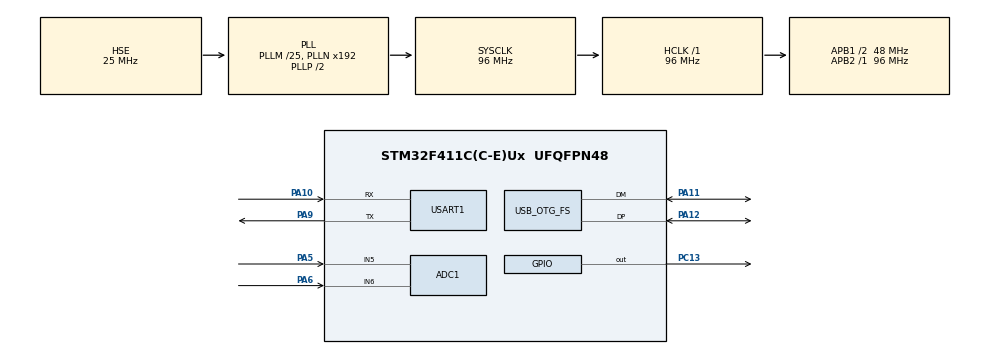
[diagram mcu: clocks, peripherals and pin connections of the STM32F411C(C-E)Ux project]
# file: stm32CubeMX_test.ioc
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ADC1.Channel-8\#ChannelRegularConversion=ADC_CHANNEL_5
ADC1.Channel-9\#ChannelRegularConversion=ADC_CHANNEL_6
ADC1.ClockPrescaler=ADC_CLOCK_SYNC_PCLK_DIV4
ADC1.InjNumberOfConversion=0
ADC1.NbrOfConversion=2
ADC1.NbrOfConversionFlag=1
ADC1.Rank-8\#ChannelRegularConversion=1
ADC1.Rank-9\#ChannelRegularConversion=2
ADC1.SamplingTime-8\#ChannelRegularConversion=ADC_SAMPLETIME_84CYCLES
ADC1.SamplingTime-9\#ChannelRegularConversion=ADC_SAMPLETIME_84CYCLES
ADC1.ScanConvMode=ENABLE
ADC1.master=1
Dma.ADC1.1.Direction=DMA_PERIPH_TO_MEMORY
Dma.ADC1.1.FIFOMode=DMA_FIFOMODE_DISABLE
Dma.ADC1.1.Instance=DMA2_Stream0
Dma.ADC1.1.MemDataAlignment=DMA_MDATAALIGN_HALFWORD
Dma.ADC1.1.MemInc=DMA_MINC_ENABLE
Dma.ADC1.1.Mode=DMA_NORMAL
Dma.ADC1.1.PeriphDataAlignment=DMA_PDATAALIGN_HALFWORD
Dma.ADC1.1.PeriphInc=DMA_PINC_DISABLE
Dma.ADC1.1.Priority=DMA_PRIORITY_LOW
Dma.Request0=USART1_TX
Dma.Request1=ADC1
Dma.USART1_TX.0.Direction=DMA_MEMORY_TO_PERIPH
Dma.USART1_TX.0.FIFOMode=DMA_FIFOMODE_DISABLE
Dma.USART1_TX.0.Instance=DMA2_Stream7
Dma.USART1_TX.0.MemDataAlignment=DMA_MDATAALIGN_BYTE
Dma.USART1_TX.0.MemInc=DMA_MINC_ENABLE
Dma.USART1_TX.0.Mode=DMA_NORMAL
Dma.USART1_TX.0.PeriphDataAlignment=DMA_PDATAALIGN_BYTE
Dma.USART1_TX.0.PeriphInc=DMA_PINC_DISABLE
Dma.USART1_TX.0.Priority=DMA_PRIORITY_MEDIUM
Mcu.Family=STM32F4
Mcu.Name=STM32F411C(C-E)Ux
Mcu.Package=UFQFPN48
NVIC.DMA2_Stream0_IRQn=true\:0\:0\:false\:false\:true\:false\:true\:true
NVIC.DMA2_Stream7_IRQn=true\:0\:0\:false\:false\:true\:false\:true\:true
NVIC.OTG_FS_IRQn=true\:0\:0\:false\:false\:true\:false\:true\:true
NVIC.PriorityGroup=NVIC_PRIORITYGROUP_4
NVIC.USART1_IRQn=true\:0\:0\:false\:false\:true\:true\:true\:true
PA10.Mode=Asynchronous
PA10.Signal=USART1_RX
PA11.Mode=Device_Only
PA11.Signal=USB_OTG_FS_DM
PA12.Mode=Device_Only
PA12.Signal=USB_OTG_FS_DP
PA5.Signal=ADCx_IN5
PA6.Signal=ADCx_IN6
PA9.Mode=Asynchronous
PA9.Signal=USART1_TX
PC13-ANTI_TAMP.Signal=GPIO_Output
PH0\ -\ OSC_IN.Mode=HSE-External-Oscillator
PH0\ -\ OSC_IN.Signal=RCC_OSC_IN
PH1\ -\ OSC_OUT.Mode=HSE-External-Oscillator
PH1\ -\ OSC_OUT.Signal=RCC_OSC_OUT
ProjectManager.HeapSize=0x1000
ProjectManager.StackSize=0x800
ProjectManager.TargetToolchain=STM32CubeIDE
RCC.48MHZClocksFreq_Value=48000000
RCC.AHBFreq_Value=96000000
RCC.APB1CLKDivider=RCC_HCLK_DIV2
RCC.APB1Freq_Value=48000000
RCC.APB1TimFreq_Value=96000000
RCC.APB2Freq_Value=96000000
RCC.APB2TimFreq_Value=96000000
RCC.CortexFreq_Value=96000000
RCC.HCLKFreq_Value=96000000
RCC.HSE_VALUE=25000000
RCC.HSI_VALUE=16000000
RCC.LSE_VALUE=32768
RCC.PLLM=25
RCC.SYSCLKFreq_VALUE=96000000
RCC.SYSCLKSource=RCC_SYSCLKSOURCE_PLLCLK
RCC.VCOOutputFreq_Value=192000000
SH.ADCx_IN5.0=ADC1_IN5,IN5
SH.ADCx_IN6.0=ADC1_IN6,IN6
USART1.VirtualMode=VM_ASYNC
USB_DEVICE.CLASS_NAME_FS=CDC
USB_DEVICE.VirtualMode=Cdc
USB_DEVICE.VirtualModeFS=Cdc_FS
USB_OTG_FS.VirtualMode=Device_Only
VP_USB_DEVICE_VS_USB_DEVICE_CDC_FS.Mode=CDC_FS
board=custom

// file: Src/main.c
/* USER CODE BEGIN Header */
/**
  ******************************************************************************
  * @file           : main.c
  * @brief          : Main program body
  ******************************************************************************
  * @attention
  *
  * Copyright (c) 2026 STMicroelectronics.
  * All rights reserved.
  *
  * This software is licensed under terms that can be found in the LICENSE file
  * in the root directory of this software component.
  * If no LICENSE file comes with this software, it is provided AS-IS.
  *
  ******************************************************************************
  */
/* USER CODE END Header */
#include "main.h"
#include "usb_device.h"

/* USER CODE BEGIN Includes */
#include <stdbool.h>
/* USER CODE END Includes */

ADC_HandleTypeDef hadc1;
DMA_HandleTypeDef hdma_adc1;

UART_HandleTypeDef huart1;
DMA_HandleTypeDef hdma_usart1_tx;

void SystemClock_Config(void);
static void MX_GPIO_Init(void);
static void MX_DMA_Init(void);
static void MX_ADC1_Init(void);
static void MX_USART1_UART_Init(void);

int main(void)
{

  /* MCU Configuration--------------------------------------------------------*/

  /* Reset of all peripherals, Initializes the Flash interface and the Systick. */
  HAL_Init();

  /* Configure the system clock */
  SystemClock_Config();

  /* Initialize all configured peripherals */
  MX_GPIO_Init();
  MX_DMA_Init();
  MX_USB_DEVICE_Init();
  MX_ADC1_Init();
  MX_USART1_UART_Init();

  /* Infinite loop */
  /* USER CODE BEGIN WHILE */
  main_cpp();
  while (1)
  {
    /* USER CODE END WHILE */

  }
}

void SystemClock_Config(void)
{
  RCC_OscInitTypeDef RCC_OscInitStruct = {0};
  RCC_ClkInitTypeDef RCC_ClkInitStruct = {0};

  /** Configure the main internal regulator output voltage
  */
  __HAL_RCC_PWR_CLK_ENABLE();
  __HAL_PWR_VOLTAGESCALING_CONFIG(PWR_REGULATOR_VOLTAGE_SCALE1);

  /** Initializes the RCC Oscillators according to the specified parameters
  * in the RCC_OscInitTypeDef structure.
  */
  RCC_OscInitStruct.OscillatorType = RCC_OSCILLATORTYPE_HSE;
  RCC_OscInitStruct.HSEState = RCC_HSE_ON;
  RCC_OscInitStruct.PLL.PLLState = RCC_PLL_ON;
  RCC_OscInitStruct.PLL.PLLSource = RCC_PLLSOURCE_HSE;
  RCC_OscInitStruct.PLL.PLLM = 25;
  RCC_OscInitStruct.PLL.PLLN = 192;
  RCC_OscInitStruct.PLL.PLLP = RCC_PLLP_DIV2;
  RCC_OscInitStruct.PLL.PLLQ = 4;
  if (HAL_RCC_OscConfig(&RCC_OscInitStruct) != HAL_OK)
  {
    Error_Handler();
  }

  /** Initializes the CPU, AHB and APB buses clocks
  */
  RCC_ClkInitStruct.ClockType = RCC_CLOCKTYPE_HCLK|RCC_CLOCKTYPE_SYSCLK
                              |RCC_CLOCKTYPE_PCLK1|RCC_CLOCKTYPE_PCLK2;
  RCC_ClkInitStruct.SYSCLKSource = RCC_SYSCLKSOURCE_PLLCLK;
  RCC_ClkInitStruct.AHBCLKDivider = RCC_SYSCLK_DIV1;
  RCC_ClkInitStruct.APB1CLKDivider = RCC_HCLK_DIV2;
  RCC_ClkInitStruct.APB2CLKDivider = RCC_HCLK_DIV1;

  if (HAL_RCC_ClockConfig(&RCC_ClkInitStruct, FLASH_LATENCY_3) != HAL_OK)
  {
    Error_Handler();
  }
}

static void MX_ADC1_Init(void)
{

  ADC_ChannelConfTypeDef sConfig = {0};

  /** Configure the global features of the ADC (Clock, Resolution, Data Alignment and number of conversion)
  */
  hadc1.Instance = ADC1;
  hadc1.Init.ClockPrescaler = ADC_CLOCK_SYNC_PCLK_DIV4;
  hadc1.Init.Resolution = ADC_RESOLUTION_12B;
  hadc1.Init.ScanConvMode = ENABLE;
  hadc1.Init.ContinuousConvMode = DISABLE;
  hadc1.Init.DiscontinuousConvMode = DISABLE;
  hadc1.Init.ExternalTrigConvEdge = ADC_EXTERNALTRIGCONVEDGE_NONE;
  hadc1.Init.ExternalTrigConv = ADC_SOFTWARE_START;
  hadc1.Init.DataAlign = ADC_DATAALIGN_RIGHT;
  hadc1.Init.NbrOfConversion = 2;
  hadc1.Init.DMAContinuousRequests = DISABLE;
  hadc1.Init.EOCSelection = ADC_EOC_SINGLE_CONV;
  if (HAL_ADC_Init(&hadc1) != HAL_OK)
  {
    Error_Handler();
  }

  /** Configure for the selected ADC regular channel its corresponding rank in the sequencer and its sample time.
  */
  sConfig.Channel = ADC_CHANNEL_5;
  sConfig.Rank = 1;
  sConfig.SamplingTime = ADC_SAMPLETIME_84CYCLES;
  if (HAL_ADC_ConfigChannel(&hadc1, &sConfig) != HAL_OK)
  {
    Error_Handler();
  }

  /** Configure for the selected ADC regular channel its corresponding rank in the sequencer and its sample time.
  */
  sConfig.Channel = ADC_CHANNEL_6;
  sConfig.Rank = 2;
  if (HAL_ADC_ConfigChannel(&hadc1, &sConfig) != HAL_OK)
  {
    Error_Handler();
  }

}

static void MX_USART1_UART_Init(void)
{

  huart1.Instance = USART1;
  huart1.Init.BaudRate = 115200;
  huart1.Init.WordLength = UART_WORDLENGTH_8B;
  huart1.Init.StopBits = UART_STOPBITS_1;
  huart1.Init.Parity = UART_PARITY_NONE;
  huart1.Init.Mode = UART_MODE_TX_RX;
  huart1.Init.HwFlowCtl = UART_HWCONTROL_NONE;
  huart1.Init.OverSampling = UART_OVERSAMPLING_16;
  if (HAL_UART_Init(&huart1) != HAL_OK)
  {
    Error_Handler();
  }

}

static void MX_DMA_Init(void)
{

  /* DMA controller clock enable */
  __HAL_RCC_DMA2_CLK_ENABLE();

  /* DMA interrupt init */
  /* DMA2_Stream0_IRQn interrupt configuration */
  HAL_NVIC_SetPriority(DMA2_Stream0_IRQn, 0, 0);
  HAL_NVIC_EnableIRQ(DMA2_Stream0_IRQn);
  /* DMA2_Stream7_IRQn interrupt configuration */
  HAL_NVIC_SetPriority(DMA2_Stream7_IRQn, 0, 0);
  HAL_NVIC_EnableIRQ(DMA2_Stream7_IRQn);

}

static void MX_GPIO_Init(void)
{
  GPIO_InitTypeDef GPIO_InitStruct = {0};

  /* GPIO Ports Clock Enable */
  __HAL_RCC_GPIOC_CLK_ENABLE();
  __HAL_RCC_GPIOH_CLK_ENABLE();
  __HAL_RCC_GPIOA_CLK_ENABLE();

  /*Configure GPIO pin Output Level */
  HAL_GPIO_WritePin(GPIOC, GPIO_PIN_13, GPIO_PIN_RESET);

  /*Configure GPIO pin : PC13 */
  GPIO_InitStruct.Pin = GPIO_PIN_13;
  GPIO_InitStruct.Mode = GPIO_MODE_OUTPUT_PP;
  GPIO_InitStruct.Pull = GPIO_NOPULL;
  GPIO_InitStruct.Speed = GPIO_SPEED_FREQ_LOW;
  HAL_GPIO_Init(GPIOC, &GPIO_InitStruct);

}

void Error_Handler(void)
{
  __disable_irq();
  while (1)
  {
  }
}
